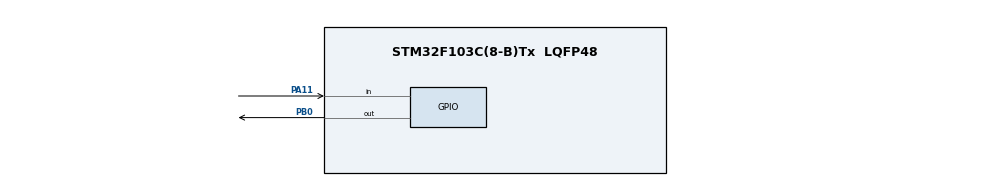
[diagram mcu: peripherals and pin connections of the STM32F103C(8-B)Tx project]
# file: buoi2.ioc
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Mcu.Family=STM32F1
Mcu.Name=STM32F103C(8-B)Tx
Mcu.Package=LQFP48
NVIC.PriorityGroup=NVIC_PRIORITYGROUP_4
PA11.GPIO_PuPd=GPIO_PULLUP
PA11.Signal=GPIO_Input
PA13.Mode=Serial_Wire
PA13.Signal=SYS_JTMS-SWDIO
PA14.Mode=Serial_Wire
PA14.Signal=SYS_JTCK-SWCLK
PB0.GPIO_PuPd=GPIO_NOPULL
PB0.Signal=GPIO_Output
ProjectManager.HeapSize=0x200
ProjectManager.StackSize=0x400
ProjectManager.TargetToolchain=STM32CubeIDE
RCC.APB1Freq_Value=8000000
RCC.APB2Freq_Value=8000000
board=custom

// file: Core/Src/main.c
/* USER CODE BEGIN Header */
/**
  ******************************************************************************
  * @file           : main.c
  * @brief          : Main program body
  ******************************************************************************
  * @attention
  *
  * <h2><center>&copy; Copyright (c) 2020 STMicroelectronics.
  * All rights reserved.</center></h2>
  *
  * This software component is licensed by ST under BSD 3-Clause license,
  * the "License"; You may not use this file except in compliance with the
  * License. You may obtain a copy of the License at:
  *                        opensource.org/licenses/BSD-3-Clause
  *
  ******************************************************************************
  */
/* USER CODE END Header */
#include "main.h"

void SystemClock_Config(void);
static void MX_GPIO_Init(void);
/* USER CODE BEGIN PFP */
void My_GPIO_Init()
{
	HAL_RCC_GPIOA_CLK_ENABLE();
	HAL_RCC_GPIOB_CLK_ENABLE();

	uint32_t *GPIOA_CRH = (uint32_t*)0x40010804;
	uint32_t *GPIOA_IDR = (uint32_t*)0x40010808;
	uint32_t *GPIOB_ODR = (uint32_t*)0x40010C0C;
	uint32_t *GPIOB_CRL = (uint32_t*)0x40010C00;

	*GPIOA_CRH = 8<<12;
	*GPIOA_IDR = 1<<11;
	*GPIOB_CRL = 3;
}
/* USER CODE END PFP */

int main(void)
{
  /* USER CODE BEGIN 1 */
	uint32_t *GPIOA_IDR = (uint32_t*)0x40010808;
	uint32_t *GPIOB_ODR = (uint32_t*)0x40010C0C;
	int co=0;
  /* USER CODE END 1 */

  /* MCU Configuration--------------------------------------------------------*/

  /* Reset of all peripherals, Initializes the Flash interface and the Systick. */
  HAL_Init();

  /* Configure the system clock */
  SystemClock_Config();

  /* Initialize all configured peripherals */
  MX_GPIO_Init();

  /* Infinite loop */
  /* USER CODE BEGIN WHILE */
  while (1)
  {
	  if((((*GPIOA_IDR)>>11)&1) !=1)
		  co++;
	  if(co>=2)
		  co=0;
	  if(co==0)
		  *GPIOB_ODR &=~1;
	  else
		  *GPIOB_ODR |= 1;
	  HAL_Delay(1000);

    /* USER CODE END WHILE */

  }
}

void SystemClock_Config(void)
{
  RCC_OscInitTypeDef RCC_OscInitStruct = {0};
  RCC_ClkInitTypeDef RCC_ClkInitStruct = {0};

  /** Initializes the RCC Oscillators according to the specified parameters
  * in the RCC_OscInitTypeDef structure.
  */
  RCC_OscInitStruct.OscillatorType = RCC_OSCILLATORTYPE_HSI;
  RCC_OscInitStruct.HSIState = RCC_HSI_ON;
  RCC_OscInitStruct.HSICalibrationValue = RCC_HSICALIBRATION_DEFAULT;
  RCC_OscInitStruct.PLL.PLLState = RCC_PLL_NONE;
  if (HAL_RCC_OscConfig(&RCC_OscInitStruct) != HAL_OK)
  {
    Error_Handler();
  }
  /** Initializes the CPU, AHB and APB buses clocks
  */
  RCC_ClkInitStruct.ClockType = RCC_CLOCKTYPE_HCLK|RCC_CLOCKTYPE_SYSCLK
                              |RCC_CLOCKTYPE_PCLK1|RCC_CLOCKTYPE_PCLK2;
  RCC_ClkInitStruct.SYSCLKSource = RCC_SYSCLKSOURCE_HSI;
  RCC_ClkInitStruct.AHBCLKDivider = RCC_SYSCLK_DIV1;
  RCC_ClkInitStruct.APB1CLKDivider = RCC_HCLK_DIV1;
  RCC_ClkInitStruct.APB2CLKDivider = RCC_HCLK_DIV1;

  if (HAL_RCC_ClockConfig(&RCC_ClkInitStruct, FLASH_LATENCY_0) != HAL_OK)
  {
    Error_Handler();
  }
}

static void MX_GPIO_Init(void)
{
  GPIO_InitTypeDef GPIO_InitStruct = {0};

  /* GPIO Ports Clock Enable */
  __HAL_RCC_GPIOB_CLK_ENABLE();
  __HAL_RCC_GPIOA_CLK_ENABLE();

  /*Configure GPIO pin Output Level */
  HAL_GPIO_WritePin(GPIOB, GPIO_PIN_0, GPIO_PIN_RESET);

  /*Configure GPIO pin : PB0 */
  GPIO_InitStruct.Pin = GPIO_PIN_0;
  GPIO_InitStruct.Mode = GPIO_MODE_OUTPUT_PP;
  GPIO_InitStruct.Pull = GPIO_NOPULL;
  GPIO_InitStruct.Speed = GPIO_SPEED_FREQ_LOW;
  HAL_GPIO_Init(GPIOB, &GPIO_InitStruct);

  /*Configure GPIO pin : PA11 */
  GPIO_InitStruct.Pin = GPIO_PIN_11;
  GPIO_InitStruct.Mode = GPIO_MODE_INPUT;
  GPIO_InitStruct.Pull = GPIO_PULLUP;
  HAL_GPIO_Init(GPIOA, &GPIO_InitStruct);

}

void Error_Handler(void)
{
  __disable_irq();
  while (1)
  {
  }
}

/************************ (C) COPYRIGHT STMicroelectronics *****END OF FILE****/
